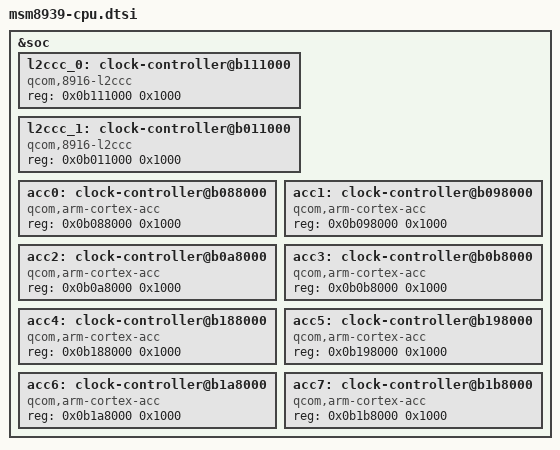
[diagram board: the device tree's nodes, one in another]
/* Copyright (c) 2014, The Linux Foundation. All rights reserved.
 *
 * This program is free software; you can redistribute it and/or modify
 * it under the terms of the GNU General Public License version 2 and
 * only version 2 as published by the Free Software Foundation.
 *
 * This program is distributed in the hope that it will be useful,
 * but WITHOUT ANY WARRANTY; without even the implied warranty of
 * MERCHANTABILITY or FITNESS FOR A PARTICULAR PURPOSE.  See the
 * GNU General Public License for more details.
 */

&soc {
	l2ccc_0: clock-controller@b111000 {
		compatible = "qcom,8916-l2ccc";
		reg = <0x0b111000 0x1000>;
	};

	l2ccc_1: clock-controller@b011000 {
		compatible = "qcom,8916-l2ccc";
		reg = <0x0b011000 0x1000>;
	};

	acc0:clock-controller@b088000 {
		compatible = "qcom,arm-cortex-acc";
		reg = <0x0b088000 0x1000>;
	};

	acc1:clock-controller@b098000 {
		compatible = "qcom,arm-cortex-acc";
		reg = <0x0b098000 0x1000>;
	};

	acc2:clock-controller@b0a8000 {
		compatible = "qcom,arm-cortex-acc";
		reg = <0x0b0a8000 0x1000>;
	};

	acc3:clock-controller@b0b8000 {
		compatible = "qcom,arm-cortex-acc";
		reg = <0x0b0b8000 0x1000>;
	};

	acc4:clock-controller@b188000 {
		compatible = "qcom,arm-cortex-acc";
		reg = <0x0b188000 0x1000>;
	};

	acc5:clock-controller@b198000 {
		compatible = "qcom,arm-cortex-acc";
		reg = <0x0b198000 0x1000>;
	};

	acc6:clock-controller@b1a8000 {
		compatible = "qcom,arm-cortex-acc";
		reg = <0x0b1a8000 0x1000>;
	};

	acc7:clock-controller@b1b8000 {
		compatible = "qcom,arm-cortex-acc";
		reg = <0x0b1b8000 0x1000>;
	};
};
